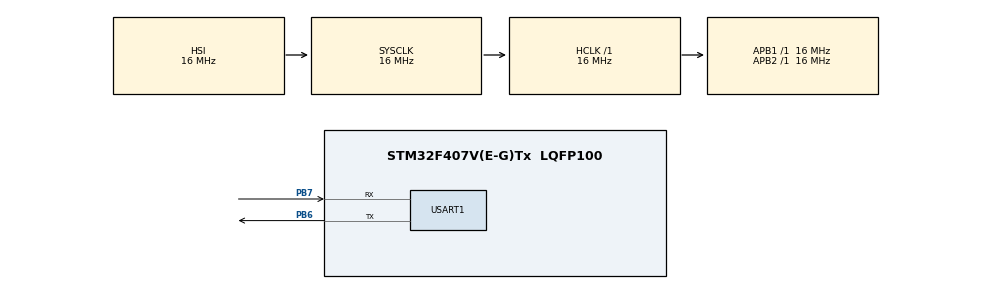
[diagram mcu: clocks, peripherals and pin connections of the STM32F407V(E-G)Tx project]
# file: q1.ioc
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Mcu.Family=STM32F4
Mcu.Name=STM32F407V(E-G)Tx
Mcu.Package=LQFP100
NVIC.PriorityGroup=NVIC_PRIORITYGROUP_4
NVIC.USART1_IRQn=true\:0\:0\:false\:false\:true\:true
PB6.Mode=Asynchronous
PB6.Signal=USART1_TX
PB7.Mode=Asynchronous
PB7.Signal=USART1_RX
PH0-OSC_IN.Mode=HSE-External-Oscillator
PH0-OSC_IN.Signal=RCC_OSC_IN
PH1-OSC_OUT.Mode=HSE-External-Oscillator
PH1-OSC_OUT.Signal=RCC_OSC_OUT
ProjectManager.HeapSize=0x200
ProjectManager.StackSize=0x400
ProjectManager.TargetToolchain=MDK-ARM V5
RCC.48MHZClocksFreq_Value=131250000
RCC.AHBFreq_Value=16000000
RCC.APB1Freq_Value=16000000
RCC.APB2Freq_Value=16000000
RCC.CortexFreq_Value=16000000
RCC.HSE_VALUE=25000000
RCC.HSI_VALUE=16000000
RCC.LSE_VALUE=32768
RCC.PLLN=336
RCC.PLLSourceVirtual=RCC_PLLSOURCE_HSE
RCC.SYSCLKFreq_VALUE=16000000
RCC.VCOOutputFreq_Value=525000000
USART1.VirtualMode=VM_ASYNC
board=custom

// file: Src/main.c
/**
  ******************************************************************************
  * @file           : main.c
  * @brief          : Main program body
  ******************************************************************************
  ** This notice applies to any and all portions of this file
  * that are not between comment pairs USER CODE BEGIN and
  * USER CODE END. Other portions of this file, whether
  * inserted by the user or by software development tools
  * are owned by their respective copyright owners.
  *
  * COPYRIGHT(c) 2019 STMicroelectronics
  *
  * Redistribution and use in source and binary forms, with or without modification,
  * are permitted provided that the following conditions are met:
  *   1. Redistributions of source code must retain the above copyright notice,
  *      this list of conditions and the following disclaimer.
  *   2. Redistributions in binary form must reproduce the above copyright notice,
  *      this list of conditions and the following disclaimer in the documentation
  *      and/or other materials provided with the distribution.
  *   3. Neither the name of STMicroelectronics nor the names of its contributors
  *      may be used to endorse or promote products derived from this software
  *      without specific prior written permission.
  *
  * THIS SOFTWARE IS PROVIDED BY THE COPYRIGHT HOLDERS AND CONTRIBUTORS "AS IS"
  * AND ANY EXPRESS OR IMPLIED WARRANTIES, INCLUDING, BUT NOT LIMITED TO, THE
  * IMPLIED WARRANTIES OF MERCHANTABILITY AND FITNESS FOR A PARTICULAR PURPOSE ARE
  * DISCLAIMED. IN NO EVENT SHALL THE COPYRIGHT HOLDER OR CONTRIBUTORS BE LIABLE
  * FOR ANY DIRECT, INDIRECT, INCIDENTAL, SPECIAL, EXEMPLARY, OR CONSEQUENTIAL
  * DAMAGES (INCLUDING, BUT NOT LIMITED TO, PROCUREMENT OF SUBSTITUTE GOODS OR
  * SERVICES; LOSS OF USE, DATA, OR PROFITS; OR BUSINESS INTERRUPTION) HOWEVER
  * CAUSED AND ON ANY THEORY OF LIABILITY, WHETHER IN CONTRACT, STRICT LIABILITY,
  * OR TORT (INCLUDING NEGLIGENCE OR OTHERWISE) ARISING IN ANY WAY OUT OF THE USE
  * OF THIS SOFTWARE, EVEN IF ADVISED OF THE POSSIBILITY OF SUCH DAMAGE.
  *
  ******************************************************************************
  */
#include "main.h"
#include "stm32f4xx_hal.h"
#include "usart.h"
#include "gpio.h"
#include "mbed.h"

char* bufftr = "Hello UART!";
uint8_t x;
char* b = "\n\r";
uint8_t y;
/* USER CODE BEGIN PV */
/* Private variables ---------------------------------------------------------*/

/* USER CODE END PV */

void SystemClock_Config(void);

/* USER CODE BEGIN PFP */
/* Private function prototypes -----------------------------------------------*/

/* USER CODE END PFP */

int main(void)
{

  /* MCU Configuration----------------------------------------------------------*/

  /* Reset of all peripherals, Initializes the Flash interface and the Systick. */
  HAL_Init();

  /* Configure the system clock */
  SystemClock_Config();

  /* Initialize all configured peripherals */
  MX_GPIO_Init();
  MX_USART1_UART_Init();
  /* USER CODE BEGIN 2 */
	__HAL_UART_ENABLE_IT(&huart1, UART_IT_TC);
	Serial pc(USBTX, USBRX);
  /* USER CODE END 2 */

  /* Infinite loop */
  /* USER CODE BEGIN WHILE */
  while (1)
  {
		HAL_UART_Transmit_IT(&huart1, (uint*_t *)bufftr,8);
		HAL_UART_Transmit_IT(&huart1, (uint*_t *)x,8);
		HAL_UART_Transmit_IT(&huart1, (uint*_t *)b,8);
		if((x++)==20000)
		{
			switch (++y)
				case 1:
					pc.baud (9600);
				case 2:
					pc.baud (1000000);
			x = 0;
		}
		HAL_DELAY(200);
  /* USER CODE END WHILE */

  }

}

void SystemClock_Config(void)
{

  RCC_OscInitTypeDef RCC_OscInitStruct;
  RCC_ClkInitTypeDef RCC_ClkInitStruct;

    /**Configure the main internal regulator output voltage
    */
  __HAL_RCC_PWR_CLK_ENABLE();

  __HAL_PWR_VOLTAGESCALING_CONFIG(PWR_REGULATOR_VOLTAGE_SCALE1);

    /**Initializes the CPU, AHB and APB busses clocks
    */
  RCC_OscInitStruct.OscillatorType = RCC_OSCILLATORTYPE_HSI;
  RCC_OscInitStruct.HSIState = RCC_HSI_ON;
  RCC_OscInitStruct.HSICalibrationValue = 16;
  RCC_OscInitStruct.PLL.PLLState = RCC_PLL_NONE;
  if (HAL_RCC_OscConfig(&RCC_OscInitStruct) != HAL_OK)
  {
    _Error_Handler(__FILE__, __LINE__);
  }

    /**Initializes the CPU, AHB and APB busses clocks
    */
  RCC_ClkInitStruct.ClockType = RCC_CLOCKTYPE_HCLK|RCC_CLOCKTYPE_SYSCLK
                              |RCC_CLOCKTYPE_PCLK1|RCC_CLOCKTYPE_PCLK2;
  RCC_ClkInitStruct.SYSCLKSource = RCC_SYSCLKSOURCE_HSI;
  RCC_ClkInitStruct.AHBCLKDivider = RCC_SYSCLK_DIV1;
  RCC_ClkInitStruct.APB1CLKDivider = RCC_HCLK_DIV1;
  RCC_ClkInitStruct.APB2CLKDivider = RCC_HCLK_DIV1;

  if (HAL_RCC_ClockConfig(&RCC_ClkInitStruct, FLASH_LATENCY_0) != HAL_OK)
  {
    _Error_Handler(__FILE__, __LINE__);
  }

    /**Configure the Systick interrupt time
    */
  HAL_SYSTICK_Config(HAL_RCC_GetHCLKFreq()/1000);

    /**Configure the Systick
    */
  HAL_SYSTICK_CLKSourceConfig(SYSTICK_CLKSOURCE_HCLK);

  /* SysTick_IRQn interrupt configuration */
  HAL_NVIC_SetPriority(SysTick_IRQn, 0, 0);
}

void _Error_Handler(char *file, int line)
{
  while(1)
  {
  }
}

/************************ (C) COPYRIGHT STMicroelectronics *****END OF FILE****/
